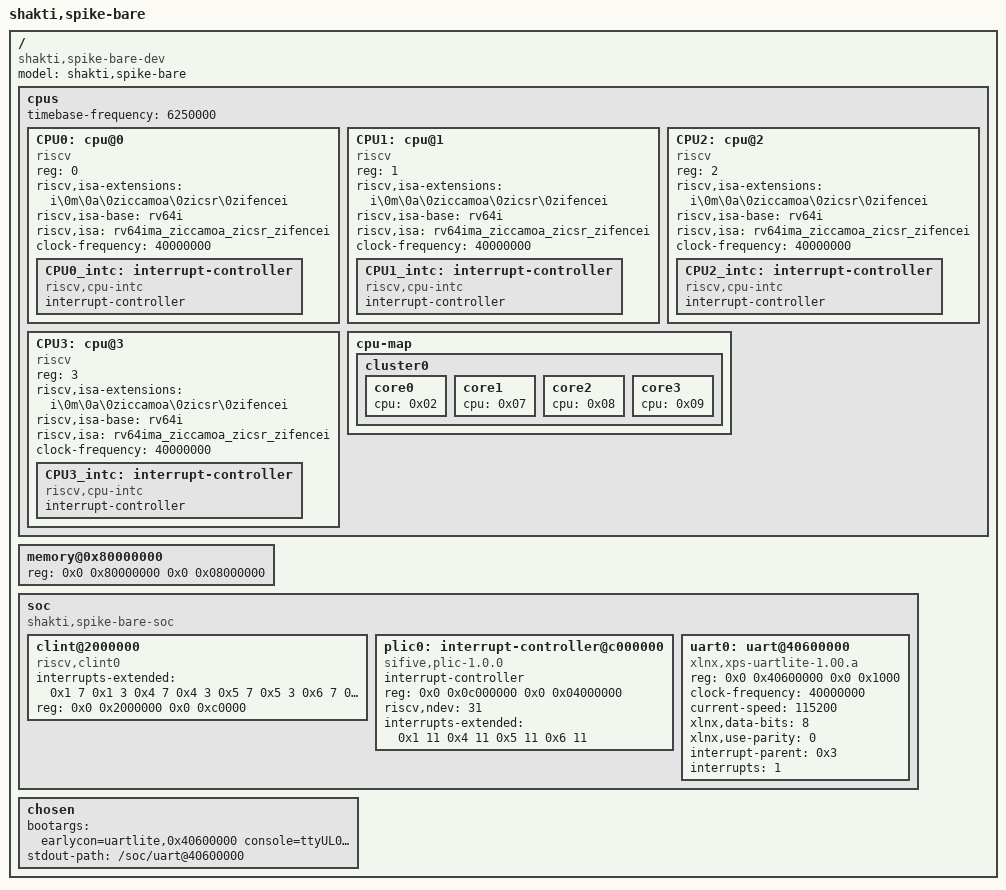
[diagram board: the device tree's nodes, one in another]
/dts-v1/;

/ {
    #address-cells = <2>;
    #size-cells = <2>;
    compatible = "shakti,spike-bare-dev";
    model = "shakti,spike-bare";

    cpus {
        #address-cells = <1>;
        #size-cells = <0>;
        timebase-frequency = <6250000>;

        CPU0: cpu@0 {
            phandle = <0x02>;
            device_type = "cpu";
            reg = <0>;
            status = "okay";
            compatible = "riscv";
            riscv,isa-extensions = "i\0m\0a\0ziccamoa\0zicsr\0zifencei";
            riscv,isa-base = "rv64i";
            riscv,isa = "rv64ima_ziccamoa_zicsr_zifencei";
            clock-frequency = <40000000>;
            CPU0_intc: interrupt-controller {
                #interrupt-cells = <1>;
                interrupt-controller;
                compatible = "riscv,cpu-intc";
                phandle = <0x1>;
            };
        };

        CPU1: cpu@1 {
            phandle = <0x07>;
            device_type = "cpu";
            reg = <1>;
            status = "okay";
            compatible = "riscv";
            riscv,isa-extensions = "i\0m\0a\0ziccamoa\0zicsr\0zifencei";
            riscv,isa-base = "rv64i";
            riscv,isa = "rv64ima_ziccamoa_zicsr_zifencei";
            clock-frequency = <40000000>;
            CPU1_intc: interrupt-controller {
                #interrupt-cells = <1>;
                interrupt-controller;
                compatible = "riscv,cpu-intc";
                phandle = <0x4>;
            };
        };

        CPU2: cpu@2 {
            phandle = <0x08>;
            device_type = "cpu";
            reg = <2>;
            status = "okay";
            compatible = "riscv";
            riscv,isa-extensions = "i\0m\0a\0ziccamoa\0zicsr\0zifencei";
            riscv,isa-base = "rv64i";
            riscv,isa = "rv64ima_ziccamoa_zicsr_zifencei";
            clock-frequency = <40000000>;
            CPU2_intc: interrupt-controller {
                #interrupt-cells = <1>;
                interrupt-controller;
                compatible = "riscv,cpu-intc";
                phandle = <0x5>;
            };
        };

        CPU3: cpu@3 {
            phandle = <0x09>;
            device_type = "cpu";
            reg = <3>;
            status = "okay";
            compatible = "riscv";
            riscv,isa-extensions = "i\0m\0a\0ziccamoa\0zicsr\0zifencei";
            riscv,isa-base = "rv64i";
            riscv,isa = "rv64ima_ziccamoa_zicsr_zifencei";
            clock-frequency = <40000000>;
            CPU3_intc: interrupt-controller {
                #interrupt-cells = <1>;
                interrupt-controller;
                compatible = "riscv,cpu-intc";
                phandle = <0x6>;
            };
        };

        cpu-map {
            cluster0 {
                core0 { cpu = <0x02>; };
                core1 { cpu = <0x07>; };
                core2 { cpu = <0x08>; };
                core3 { cpu = <0x09>; };
            };
        };
    };

    memory@0x80000000 {
        device_type = "memory";
        reg = <0x0 0x80000000 0x0 0x08000000>;
    };

    soc {
        #address-cells = <2>;
        #size-cells = <2>;
        compatible = "shakti,spike-bare-soc", "simple-bus";
        ranges;
        clint@2000000 {
            compatible = "riscv,clint0";
            interrupts-extended = <0x1 7 0x1 3 0x4 7 0x4 3 0x5 7 0x5 3 0x6 7 0x6 3>;
            reg = <0x0 0x2000000 0x0 0xc0000>;
        };

        plic0: interrupt-controller@c000000 {
            compatible = "sifive,plic-1.0.0", "riscv,plic0";
            #address-cells = <0>;
            #interrupt-cells = <1>;
            interrupt-controller;
            reg = <0x0 0x0c000000 0x0 0x04000000>;
            riscv,ndev = <31>;
            interrupts-extended = <0x1 11 0x4 11 0x5 11 0x6 11>;
            phandle = <0x3>;
        };

        uart0: uart@40600000 {
            compatible = "xlnx,xps-uartlite-1.00.a";
            reg = <0x0 0x40600000 0x0 0x1000>;
            clock-frequency = <40000000>;
            current-speed = <115200>;
            xlnx,data-bits = <8>;
            xlnx,use-parity = <0>;
            interrupt-parent = <0x3>;
            interrupts = <1>;
        };
    };

    chosen {
        bootargs = "earlycon=uartlite,0x40600000 console=ttyUL0 root=/dev/ram rw rootfstype=ramfs";
        stdout-path = "/soc/uart@40600000";
    };
};
